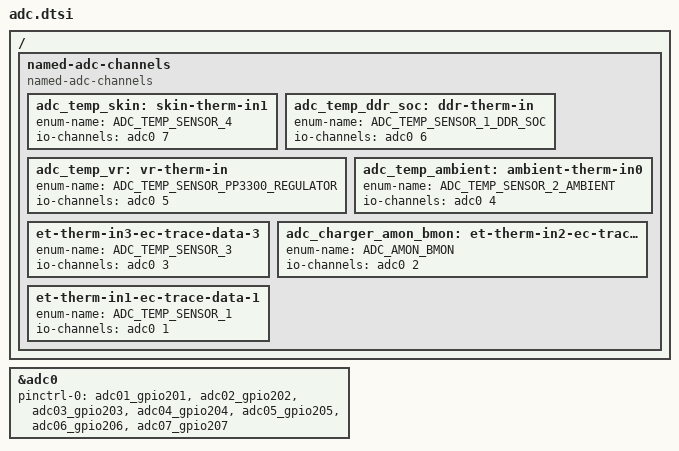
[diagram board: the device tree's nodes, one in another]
/* Copyright 2025 The ChromiumOS Authors
 * Use of this source code is governed by a BSD-style license that can be
 * found in the LICENSE file.
 */

/ {
       named-adc-channels {
               compatible = "named-adc-channels";

               adc_temp_skin: skin-therm-in1 {
                       enum-name = "ADC_TEMP_SENSOR_4";
                       io-channels = <&adc0 7>;
               };
               adc_temp_ddr_soc: ddr-therm-in {
                       enum-name = "ADC_TEMP_SENSOR_1_DDR_SOC";
                       io-channels = <&adc0 6>;
               };
               adc_temp_vr: vr-therm-in {
                       enum-name = "ADC_TEMP_SENSOR_PP3300_REGULATOR";
                       io-channels = <&adc0 5>;
               };
               adc_temp_ambient: ambient-therm-in0 {
                       enum-name = "ADC_TEMP_SENSOR_2_AMBIENT";
                       io-channels = <&adc0 4>;
               };
               et-therm-in3-ec-trace-data-3 {
                       enum-name = "ADC_TEMP_SENSOR_3";
                       io-channels = <&adc0 3>;
               };
               adc_charger_amon_bmon: et-therm-in2-ec-trace-data-2 {
                       enum-name = "ADC_AMON_BMON";
                       io-channels = <&adc0 2>;
               };
               et-therm-in1-ec-trace-data-1 {
                       enum-name = "ADC_TEMP_SENSOR_1";
                       io-channels = <&adc0 1>;
               };
       };
};

&adc0 {
       status = "okay";
       pinctrl-0 = <&adc01_gpio201
                    &adc02_gpio202
                    &adc03_gpio203
                    &adc04_gpio204
                    &adc05_gpio205
                    &adc06_gpio206
                    &adc07_gpio207>;
       pinctrl-names = "default";
};
